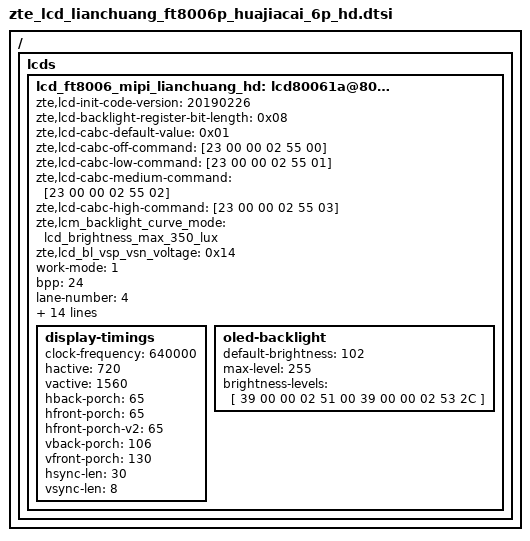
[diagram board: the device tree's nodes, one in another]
/ { lcds {
	lcd_ft8006_mipi_lianchuang_hd: lcd80061a@80061a {
		zte,lcd-init-code-version = "20190226";
		zte,lcd-backlight-register-bit-length = <0x08>;
		zte,lcd-cabc-default-value = <0x01>;
		zte,lcd-cabc-off-command = [23 00 00 02 55 00];
		zte,lcd-cabc-low-command = [23 00 00 02 55 01];
		zte,lcd-cabc-medium-command = [23 00 00 02 55 02];
		zte,lcd-cabc-high-command = [23 00 00 02 55 03];
		zte,lcm_backlight_curve_mode = "lcd_brightness_max_350_lux";
		zte,lcd_bl_vsp_vsn_voltage = <0x14>;

		work-mode = <1>;
		bpp = <24>;
		lane-number = <4>;

		need-check-esd = <3>;
		esd-timeout = <2000>;

		fps = <60>;
		fps-v2 = <60>;
		width-mm = <64>;
		height-mm = <140>;
		panel-name = "lcd_ft8006_mipi_lianchuang_hd";

		power-on-sequence = <
					4   1  1
					5   1  8
					50  1  5
					50  0  1
					50  1  10
					>;
		power-off-sequence = <
					50  1  10
					5   0	5
					4   0   5
					>;

		init-data = [
39 00 00 02 41 5a
39 00 00 02 4c 03
39 00 00 03 41 5a 09
39 00 00 06 80 64 00 64 00 00
39 00 00 03 41 5a 0a
39 00 00 11 80 a5 15 a5 aa a5 88 42 68 a6 03 07 01 5f 3c 50 32
39 00 00 11 90 0c 0f 22 00 2a 18 64 00 88 03 00 ee ee 00 3f 2a
39 00 00 11 a0 00 30 02 32 11 0d 60 01 ff ff 03 40 42 0f 94 11
39 00 00 11 b0 e8 03 00 00 11 0d 60 00 ff ff 03 ff 34 0c 0f 0e
39 00 00 0b c0 1f 03 00 08 20 34 00 00 00 00
39 00 00 03 41 5a 0b
39 00 00 11 80 ff a0 a0 00 00 0a 1f 32 3c 47 58 65 66 73 74 87
39 00 00 11 90 7d 6c 6e 63 5b 50 40 36 2c 1b 07 01 00 0a 1f 32
39 00 00 11 a0 3c 47 58 65 66 73 74 87 7d 6c 6e 63 5b 50 40 36
39 00 00 06 b0 2c 1b 07 01 00
39 00 00 03 41 5a 0c
39 00 00 11 80 00 00 20 42 00 00 80 05 54 00 00 00 20 42 00 00
39 00 00 03 90 80 05
39 00 00 03 41 5a 0d
39 00 00 11 80 7a d0 02 18 06 fa 00 f0 00 0a 0a 0a 0a 00 01 03
39 00 00 11 90 00 00 00 00 ac a2 2a 00 00 00 ac a2 2a 57 31 00
39 00 00 11 a0 00 00 00 00 00 ac a2 2a aa c2 2a ac a2 2a aa c2
39 00 00 07 b0 2a 00 00 00 aa 52
39 00 00 03 41 5a 0e
39 00 00 0d 80 f0 b1 71 ef 4b 20 37 0f aa aa 00 00
39 00 00 03 41 5a 0f
39 00 00 0c 80 ff 00 55 55 23 88 88 1c 00 5a 5a
39 00 00 03 41 5a 10
39 00 00 11 80 b5 45 09 18 01 3c 94 32 10 c4 c4 04 00 60 c0 00
39 00 00 11 90 04 00 00 86 10 31 98 34 34 34 26 26 3e 1a 62 20
39 00 00 05 a0 0c 40 00 8a
39 00 00 03 41 5a 11
39 00 00 11 80 00 00 03 e7 1f 17 20 48 60 d2 8f 1a 30 88 41 8a
39 00 00 10 90 39 28 a9 c5 9a 7b f0 07 7e e0 07 7e 20 10 00
39 00 00 03 41 5a 12
39 00 00 11 80 00 00 00 00 00 00 00 00 00 00 00 00 00 00 41 37
39 00 00 11 90 2d 23 19 0f 05 fb f1 e7 00 00 00 00 00 00 00 00
39 00 00 11 a0 00 00 00 00 00 00 00 00 00 00 00 00 00 00 00 00
39 00 00 11 b0 00 00 00 00 00 00 00 00 00 2d 23 05 fb 00 2d 23
39 00 00 05 c0 05 fb 00 01
39 00 00 03 41 5a 13
39 00 00 11 80 fd 0f 00 0c 00 80 80 82 00 07 22 06 e7 b9 86 1a
39 00 00 11 90 32 00 a2 2d 65 00 00 00 00 d0 c9 b7 fe 26 6f 32
39 00 00 04 a0 22 90 04
39 00 00 03 41 5a 14
39 00 00 11 80 01 02 40 5e d1 df ef f7 fb fd 02 00 80 0b 8b 0d
39 00 00 11 90 fc fc c0 16 54 24 04 36 21 f2 20 10 2b 23 f8 00
39 00 00 11 a0 00 f8 fd 00 00 c0 ef 07 00 3f 16 6b c5 ef 8f 40
39 00 00 11 b0 b0 13 bf 3f 02 00 00 00 00 a8 62 2a 56 00 80 42
39 00 00 11 c0 a1 f0 06 fa 73 01 a3 00 5e 40 7f 2e 60 14 c0 2b
39 00 00 11 d0 e8 cf 05 8c 02 78 09 fd b9 80 51 00 af a1 3f 17
39 00 00 11 e0 30 06 e0 45 f4 e7 02 46 01 bc 8a fe 5c c0 28 80
39 00 00 11 f0 97 d1 9f 0b 18 05 30 06 7e 3f 14 00 00 00 00 00
39 00 00 03 41 5a 15
39 00 00 11 80 00 00 00 00 00 00 00 00 00 00 00 00 0c 80 ff ef
39 00 00 11 90 27 03 1b d6 88 51 ab 0d a1 d5 3e 62 d4 6a 43 68
39 00 00 11 a0 b5 00 00 00 00 00 00 00 00 00 00 00 00 00 00 00
39 00 00 11 b0 00 00 00 00 00 00 00 00 26 00 e0 01 28 54 ab ae
39 00 00 11 c0 66 db b6 ad a3 b4 ad 21 44 6d db b6 6d 0b b5 ab
39 00 00 11 d0 6a b6 6d db 02 44 db 22 8c d4 b6 6d db b6 52 ab
39 00 00 11 e0 ae 66 db b6 2d 83 b4 2d 01 40 6d db b6 6d 1b b5
39 00 00 11 f0 ab 6a b6 6d db 0a 46 db 2a 0e d5 b6 6d db b6 00
39 00 00 03 41 5a 16
39 00 00 11 80 00 00 00 00 00 00 00 00 00 00 00 00 00 00 00 00
39 00 00 0b 90 00 00 00 00 a0 41 28 01 00 00
39 00 00 03 41 5a 18
39 00 00 11 80 ef bd f7 de 7b ef bd 07 08 08 0a 0c 0c 0c 0c 0c
39 00 00 11 90 0c 0c 0c 5c 09 a8 aa aa aa aa aa aa aa aa aa 5a
39 00 00 11 a0 59 59 59 59 59 59 59 59 59 59 59 09 04 ff 00 80
39 00 00 10 b0 80 00 04 20 00 01 08 40 00 02 10 80 00 04 00
39 00 00 03 41 5a 19
39 00 00 11 80 c4 b5 a6 9b 93 8c 86 81 80 80 80 80 77 f7 ff ff
39 00 00 11 90 ff 0f f0 bf 7f 4f 0f ff af b5 71 0e 6c 4a 69 08
39 00 00 05 a0 04 04 02 00
39 00 00 03 41 5a 1a
39 00 00 11 80 ff 00 04 08 0c 00 10 14 18 1c 00 20 27 2f 37 fc
39 00 00 11 90 3f 47 4f 57 ab 5f 67 6f 77 56 7f 87 8e 96 f0 9e
39 00 00 11 a0 a6 ae b6 6b be c6 ce d5 c1 dd e5 ec f4 56 f8 fa
39 00 00 11 b0 fb 15 00 04 07 0b f0 0f 13 17 1b 6a 1f 27 2e 36
39 00 00 11 c0 b1 3e 46 4e 55 c6 5d 65 6d 75 1b 7d 84 8c 94 ac
39 00 00 11 d0 9c a4 ac b3 c1 bb c3 cb d3 16 db e2 ea f2 bc f6
39 00 00 11 e0 f8 f9 16 00 04 07 0b f0 0f 13 17 1b af 1f 27 2f
39 00 00 11 f0 37 fa 3f 47 4f 57 ff 5f 67 6f 77 af 7f 87 8f 97
39 00 00 03 41 5a 1b
39 00 00 11 80 05 9e a6 ae b6 6f be c6 ce d6 01 de e6 f0 f8 00
39 00 00 06 90 fc fe ff 00 00
39 00 00 03 41 5a 1c
39 00 00 11 80 33 22 00 03 5a 02 5a 54 e5 ff c7 20 18 28 18 08
39 00 00 11 90 10 0c 07 09 06 06 0a 10 0c 09 0b 06 26 f2 78 40
39 00 00 11 a0 20 08 08 06 13 c0 34 1e 0a 08 66 d1 a0 1c 20 20
39 00 00 11 b0 18 04 20 00 c0 04 28 01 4c 00 23 18 10 0a 06 c9
39 00 00 11 c0 04 70 41 58 54 b5 4a 55 15 00 78 f8 99 99 99 99
39 00 00 11 d0 99 99 88 88 88 88 88 88 08 c4 e3 81 00 20 80 27
39 00 00 11 e0 e2 89 00 00 00 00 40 00 80 30 04 41 06 00 00 00
39 00 00 11 f0 00 92 24 49 92 04 00 00 00 00 92 04 00 c0 03 40
39 00 00 03 41 5a 1d
39 00 00 11 80 00 01 54 0b 23 18 00 00 80 00 00 00 00 00 00 00
39 00 00 03 41 5a 22
39 00 00 10 80 00 5e 00 00 00 00 00 00 5e 00 00 00 00 00 00
39 00 00 03 41 5a 24
39 00 00 11 80 2d d3 00 55 55 55 55 54 55 55 55 9f 00 22 3e 00
39 00 00 05 90 00 00 00 00
39 00 00 03 41 5a 25
39 00 00 11 80 01 05 00 05 00 00 00 00 00 00 00 00 00 00 00 ff
39 00 00 0c 90 0f 00 00 24 00 00 00 00 ff 07 35
39 00 00 03 41 5a 26
39 00 00 11 80 00 83 00 ff ff 60 00 01 00 00 00 00 00 00 f9 9a
39 00 00 04 90 5a a5 5a
39 00 00 02 90 a5
39 00 00 03 41 00 2f
39 00 00 02 35 00
39 00 00 02 51 00
39 00 00 02 53 24
39 00 00 02 55 01
39 00 00 02 5e 04
05 78 00 01 11
05 28 00 01 29
			];
		sleep-in = [
			13 0A 00 01 28
			13 78 00 01 10
			];
		sleep-out = [
			13 78 00 01 11
			13 64 00 01 29
			];

		display-timings {
			clock-frequency = <640000>;
			hactive = <720>;
			vactive = <1560>;
			hback-porch = <65>;
			hfront-porch = <65>;
			hfront-porch-v2 = <65>;
			vback-porch = <106>;
			vfront-porch = <130>;
			hsync-len = <30>;
			vsync-len = <8>;
		};
		oled-backlight {
			default-brightness = <102>;
			max-level = <255>;
			brightness-levels = [
				39 00 00 02 51 00
				39 00 00 02 53 2C
			];
		};
	};
};};

